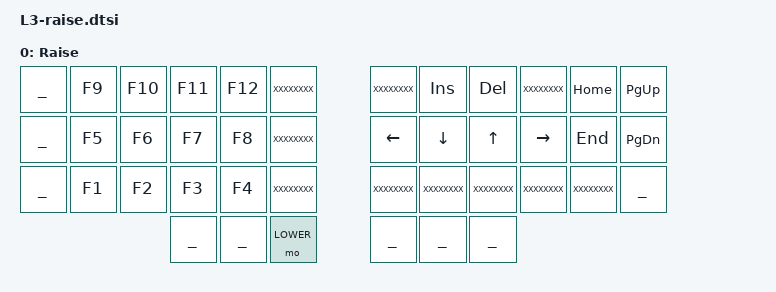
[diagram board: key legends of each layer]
/**
 * Numeric,
 */

/ {
  keymap {
    compatible = "zmk,keymap";

	raise_layer {
		label = "Raise";
		bindings = <
// ╭───────────────┬───────────────┬───────────────┬───────────────┬───────────────┬───────────────╮   ╭───────────────┬───────────────┬───────────────┬───────────────┬───────────────┬───────────────╮
	________        &kp F9        	&kp F10        	&kp F11        	&kp F12        	XXXXXXXX            XXXXXXXX        &kp INS        	&kp DEL        	XXXXXXXX        &kp HOME       	&kp PG_UP
// ├───────────────├───────────────┼───────────────┼───────────────┼───────────────┼───────────────┤   ├───────────────├───────────────┼───────────────┼───────────────┼───────────────┼───────────────┤
	________        &kp F5        	&kp F6        	&kp F7        	&kp F8        	XXXXXXXX            &kp LEFT        &kp DOWN        &kp UP        	&kp RIGHT       &kp END       	&kp PG_DN
// ├───────────────├───────────────┼───────────────┼───────────────┼───────────────┼───────────────┤   ├───────────────├───────────────┼───────────────┼───────────────┼───────────────┼───────────────┤
	________        &kp F1        	&kp F2        	&kp F3        	&kp F4        	XXXXXXXX       		XXXXXXXX   		XXXXXXXX        XXXXXXXX        XXXXXXXX        XXXXXXXX        ________
// ╰───────────────┴───────────────┴───────────────┼───────────────┼───────────────┼───────────────┤   ├───────────────├───────────────┼───────────────┼───────────────┴───────────────┴───────────────╯
                                    	            ________       	________        &mo LOWER           ________		________        ________
//                                                 ╰───────────────┴───────────────┴───────────────╯   ╰───────────────┴───────────────┴───────────────╯
			>;
		};
	};
};
